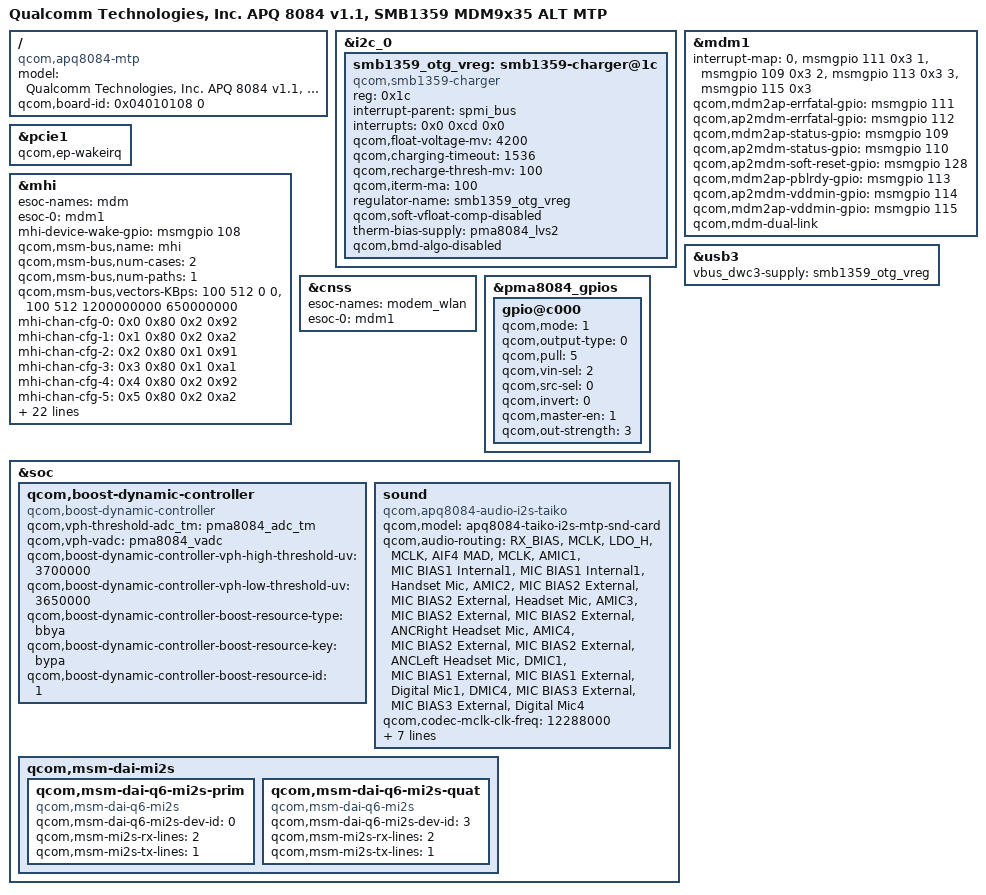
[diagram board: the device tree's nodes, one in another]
/* Copyright (c) 2013-2015, The Linux Foundation. All rights reserved.
 *
 * This program is free software; you can redistribute it and/or modify
 * it under the terms of the GNU General Public License version 2 and
 * only version 2 as published by the Free Software Foundation.
 *
 * This program is distributed in the hope that it will be useful,
 * but WITHOUT ANY WARRANTY; without even the implied warranty of
 * MERCHANTABILITY or FITNESS FOR A PARTICULAR PURPOSE.  See the
 * GNU General Public License for more details.
 */

/dts-v1/;

#include "apq8084-v1.1.dtsi"
#include "apq8084-mtp.dtsi"
#include "apq8084-taiko-i2s-codec.dtsi"

/ {
	model = "Qualcomm Technologies, Inc. APQ 8084 v1.1, SMB1359 MDM9x35 ALT MTP";
	compatible = "qcom,apq8084-mtp", "qcom,apq8084", "qcom,mtp";
	qcom,board-id = <0x04010108 0>;
};

&i2c_0 {
	smb1359_otg_vreg: smb1359-charger@1c {
		compatible = "qcom,smb1359-charger";
		reg = <0x1c>;
		interrupt-parent = <&spmi_bus>;
		interrupts = <0x0 0xcd 0x0>;	/* PMA8084 GPIO 14 */
		qcom,float-voltage-mv = <4200>;
		qcom,charging-timeout = <1536>;
		qcom,recharge-thresh-mv = <100>;
		qcom,iterm-ma = <100>;
		regulator-name = "smb1359_otg_vreg";
		qcom,soft-vfloat-comp-disabled;
		therm-bias-supply = <&pma8084_lvs2>;
		qcom,bmd-algo-disabled;
	};
};

&mdm1 {
	interrupt-map = <0 &msmgpio 111 0x3
			1 &msmgpio 109 0x3
			2 &msmgpio 113 0x3
			3 &msmgpio 115 0x3>;
	qcom,mdm2ap-errfatal-gpio = <&msmgpio 111 0x00>;
	qcom,ap2mdm-errfatal-gpio = <&msmgpio 112 0x00>;
	qcom,mdm2ap-status-gpio   = <&msmgpio 109 0x00>;
	qcom,ap2mdm-status-gpio   = <&msmgpio 110 0x00>;
	qcom,ap2mdm-soft-reset-gpio = <&msmgpio 128 0x00>;
	qcom,mdm2ap-pblrdy-gpio = <&msmgpio 113 0x00>;
	qcom,ap2mdm-vddmin-gpio = <&msmgpio 114 0x00>;
	qcom,mdm2ap-vddmin-gpio = <&msmgpio 115 0x00>;
	qcom,mdm-dual-link;
	status = "ok";
};

&pcie1 {
	qcom,ep-wakeirq;
};

&mhi {
	esoc-names = "mdm";
	esoc-0 = <&mdm1>;
	mhi-device-wake-gpio =
		<&msmgpio 108 0>;
	qcom,msm-bus,name = "mhi";
	qcom,msm-bus,num-cases = <2>;
	qcom,msm-bus,num-paths = <1>;
	qcom,msm-bus,vectors-KBps =
			<100 512 0 0>,
			<100 512 1200000000 650000000>;
	mhi-chan-cfg-0 = <0x0 0x80 0x2 0x92>;
	mhi-chan-cfg-1 = <0x1 0x80 0x2 0xa2>;
	mhi-chan-cfg-2 = <0x2 0x80 0x1 0x91>;
	mhi-chan-cfg-3 = <0x3 0x80 0x1 0xa1>;
	mhi-chan-cfg-4 = <0x4 0x80 0x2 0x92>;
	mhi-chan-cfg-5 = <0x5 0x80 0x2 0xa2>;
	mhi-chan-cfg-6 = <0x6 0xa 0x0 0x92>;
	mhi-chan-cfg-7 = <0x7 0xa 0x0 0xa2>;
	mhi-chan-cfg-10 = <0xa 0x80 0x1 0x92>;
	mhi-chan-cfg-11 = <0xb 0x80 0x1 0xa2>;
	mhi-chan-cfg-14 = <0xe 0x40 0x1 0x92>;
	mhi-chan-cfg-15 = <0xf 0x40 0x1 0xa2>;
	mhi-chan-cfg-16 = <0x10 0x40 0x1 0x92>;
	mhi-chan-cfg-17 = <0x11 0x40 0x1 0xa2>;
	mhi-chan-cfg-18 = <0x12 0x40 0x1 0x92>;
	mhi-chan-cfg-19 = <0x13 0x40 0x1 0xa2>;
	mhi-chan-cfg-20 = <0x14 0xa 0x0 0x92>;
	mhi-chan-cfg-21 = <0x15 0xa 0x0 0xa2>;
	mhi-chan-cfg-32 = <0x20 0x80 0x2 0x92>;
	mhi-chan-cfg-33 = <0x21 0x80 0x2 0xa2>;
	mhi-chan-cfg-100 = <0x64 0x80 0x3 0x52>;
	mhi-chan-cfg-101 = <0x65 0x80 0x4 0x62>;
	mhi-event-rings = <5>;
	mhi-event-cfg-0 = <0x80 0x0 0x1 0x11>;
	mhi-event-cfg-1 = <0x80 0x1 0x1 0x11>;
	mhi-event-cfg-2 = <0x80 0x2 0x5 0x11>;
	mhi-event-cfg-3 = <0x100 0x3 0x1 0x9>;
	mhi-event-cfg-4 = <0x100 0x4 0x1 0x8>;
};
&usb3 {
	vbus_dwc3-supply = <&smb1359_otg_vreg>;
};

&cnss {
	esoc-names = "modem_wlan";
	esoc-0 = <&mdm1>;
};

&pma8084_gpios {
	gpio@c000 { /* GPIO 1 */
		qcom,mode = <1>;
		qcom,output-type = <0>;		/* CMOS logic */
		qcom,pull = <5>;		/* QPNP_PIN_PULL_NO */
		qcom,vin-sel = <2>;		/* PMA8084 S4 = 1.8 V */
		qcom,src-sel = <0>;		/* GPIO */
		qcom,invert = <0>;		/* Do not invert the output */
		qcom,master-en = <1>;		/* Enable GPIO */
		qcom,out-strength = <3>;        /* High drive strength */
	};
};

&soc {
	qcom,boost-dynamic-controller {
		compatible = "qcom,boost-dynamic-controller";
		qcom,vph-threshold-adc_tm = <&pma8084_adc_tm>;
		qcom,vph-vadc = <&pma8084_vadc>;
		qcom,boost-dynamic-controller-vph-high-threshold-uv = <3700000>;
		qcom,boost-dynamic-controller-vph-low-threshold-uv = <3650000>;
		qcom,boost-dynamic-controller-boost-resource-type = "bbya";
		qcom,boost-dynamic-controller-boost-resource-key = "bypa";
		qcom,boost-dynamic-controller-boost-resource-id = <1>;
	};

	sound {
		compatible = "qcom,apq8084-audio-i2s-taiko";
		qcom,model = "apq8084-taiko-i2s-mtp-snd-card";

		qcom,audio-routing =
			"RX_BIAS", "MCLK",
			"LDO_H", "MCLK",
			"AIF4 MAD", "MCLK",
			"AMIC1", "MIC BIAS1 Internal1",
			"MIC BIAS1 Internal1", "Handset Mic",
			"AMIC2", "MIC BIAS2 External",
			"MIC BIAS2 External", "Headset Mic",
			"AMIC3", "MIC BIAS2 External",
			"MIC BIAS2 External", "ANCRight Headset Mic",
			"AMIC4", "MIC BIAS2 External",
			"MIC BIAS2 External", "ANCLeft Headset Mic",
			"DMIC1", "MIC BIAS1 External",
			"MIC BIAS1 External", "Digital Mic1",
			"DMIC4", "MIC BIAS3 External",
			"MIC BIAS3 External", "Digital Mic4";

		qcom,codec-mclk-clk-freq = <12288000>;
		qcom,cdc-micbias2-headset-only;
		qcom,mclk-ctrl-gpio  = <&pma8084_gpios 1 0>;
		qcom,prim-auxpcm-gpio-set = "prim-gpio-prim";
		pinctrl-names = "pmx-pri-mi2s-active",
				"pmx-pri-quad-mi2s-active",
				"pmx-quad-mi2s-active",
				"pmx-pri-quad-mi2s-sleep";
		pinctrl-0 = <&pri_mi2s_active &quad_mi2s_sleep>;
		pinctrl-1 = <&pri_mi2s_active &quad_mi2s_active>;
		pinctrl-2 = <&pri_mi2s_sleep &quad_mi2s_active>;
		pinctrl-3 = <&pri_mi2s_sleep &quad_mi2s_sleep>;
	};

	qcom,msm-dai-mi2s {
		qcom,msm-dai-q6-mi2s-prim {
			compatible = "qcom,msm-dai-q6-mi2s";
			qcom,msm-dai-q6-mi2s-dev-id = <0>;
			qcom,msm-mi2s-rx-lines = <2>;
			qcom,msm-mi2s-tx-lines = <1>;
		};

		qcom,msm-dai-q6-mi2s-quat {
			compatible = "qcom,msm-dai-q6-mi2s";
			qcom,msm-dai-q6-mi2s-dev-id = <3>;
			qcom,msm-mi2s-rx-lines = <2>;
			qcom,msm-mi2s-tx-lines = <1>;
		};
	};
};
